# RX64M_DTC_Pilot register map
File version: 1.0
RX64M_DTC_Pilot peripheral registers generated from iodefine.h (pilot).
Registers are 8-bit, read-write, reset 0x0 unless marked. A register's access mark holds for its fields unless they carry their own. Offsets are from the block's base; lines under a group give offsets from that group; [hi:lo] are bit positions; {n}, {i} and the like mark numbered series; 'fields as' and 'values as' point back to an identical list; <NAME> marks a mode.

## Memory map
0x00082400 DTC size 0x10

## DTC
Base 0x00082400
0x00 DTCCR reset 0x8
  [4] RRS
0x04 DTCVBR 32-bit
0x08 DTCADMOD
  [0] SHORT
0x0C DTCST
  [0] DTCST
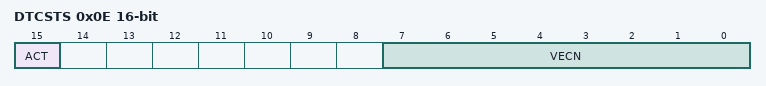
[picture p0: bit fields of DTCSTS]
0x0E DTCSTS 16-bit ro
  [15] ACT, [7:0] VECN
